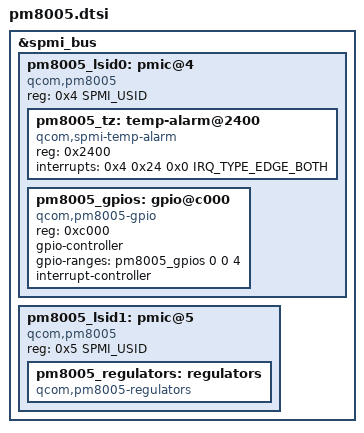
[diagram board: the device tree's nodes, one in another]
// SPDX-License-Identifier: (GPL-2.0+ OR MIT)
/* Copyright 2018 Google LLC. */

#include <dt-bindings/spmi/spmi.h>
#include <dt-bindings/interrupt-controller/irq.h>

&spmi_bus {
	pm8005_lsid0: pmic@4 {
		compatible = "qcom,pm8005", "qcom,spmi-pmic";
		reg = <0x4 SPMI_USID>;
		#address-cells = <1>;
		#size-cells = <0>;

		pm8005_tz: temp-alarm@2400 {
			compatible = "qcom,spmi-temp-alarm";
			reg = <0x2400>;
			interrupts = <0x4 0x24 0x0 IRQ_TYPE_EDGE_BOTH>;
			#thermal-sensor-cells = <0>;
		};

		pm8005_gpios: gpio@c000 {
			compatible = "qcom,pm8005-gpio", "qcom,spmi-gpio";
			reg = <0xc000>;
			gpio-controller;
			gpio-ranges = <&pm8005_gpios 0 0 4>;
			#gpio-cells = <2>;
			interrupt-controller;
			#interrupt-cells = <2>;
		};

	};

	pm8005_lsid1: pmic@5 {
		compatible = "qcom,pm8005", "qcom,spmi-pmic";
		reg = <0x5 SPMI_USID>;
		#address-cells = <1>;
		#size-cells = <0>;

		pm8005_regulators: regulators {
			compatible = "qcom,pm8005-regulators";
		};
	};
};
